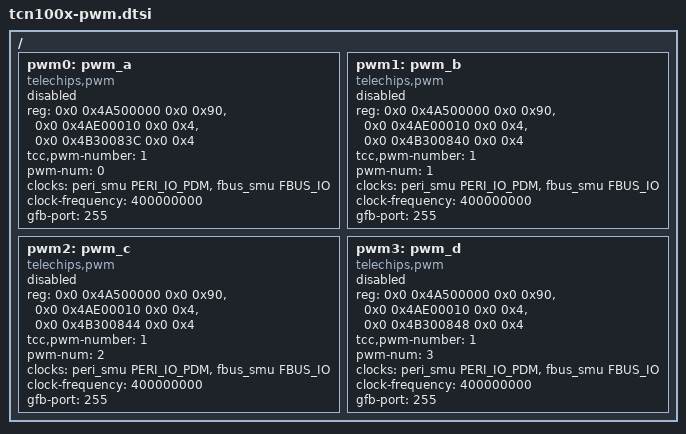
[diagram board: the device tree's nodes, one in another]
// SPDX-License-Identifier: (GPL-2.0-or-later OR MIT)
/*
 * Copyright (C) 2023 Telechips Inc.
 */

#include <dt-bindings/clock/telechips,tcn100x-clks.h>

/ {
	pwm0: pwm_a { /* pwm */
		compatible = "telechips,pwm";
		reg = <0x0 0x4A500000 0x0 0x90>,
            <0x0 0x4AE00010 0x0 0x4>,
			<0x0 0x4B30083C 0x0 0x4>;
		tcc,pwm-number = <1>;
		#pwm-cells = <2>;
		pwm-num = <0>;
		clocks = <&peri_smu PERI_IO_PDM &fbus_smu FBUS_IO>;
		clock-frequency = <400000000>;
		gfb-port = <255>;
		status = "disabled";
	};
	pwm1: pwm_b {
		compatible = "telechips,pwm";
		reg = <0x0 0x4A500000 0x0 0x90>,
            <0x0 0x4AE00010 0x0 0x4>,
			<0x0 0x4B300840 0x0 0x4>;
		tcc,pwm-number = <1>;
		#pwm-cells = <2>;
		pwm-num = <1>;
		clocks = <&peri_smu PERI_IO_PDM &fbus_smu FBUS_IO>;
		clock-frequency = <400000000>;
		gfb-port = <255>;
		status = "disabled";
	};
	pwm2: pwm_c {
		compatible = "telechips,pwm";
		reg = <0x0 0x4A500000 0x0 0x90>,
            <0x0 0x4AE00010 0x0 0x4>,
			<0x0 0x4B300844 0x0 0x4>;
		tcc,pwm-number = <1>;
		#pwm-cells = <2>;
		pwm-num = <2>;
		clocks = <&peri_smu PERI_IO_PDM &fbus_smu FBUS_IO>;
		clock-frequency = <400000000>;
		gfb-port = <255>;
		status = "disabled";
	};
	pwm3: pwm_d {
		compatible = "telechips,pwm";
		reg = <0x0 0x4A500000 0x0 0x90>,
            <0x0 0x4AE00010 0x0 0x4>,
			<0x0 0x4B300848 0x0 0x4>;
		tcc,pwm-number = <1>;
		#pwm-cells = <2>;
		pwm-num = <3>;
		clocks = <&peri_smu PERI_IO_PDM &fbus_smu FBUS_IO>;
		clock-frequency = <400000000>;
		gfb-port = <255>;
		status = "disabled";
	};
};
